# STM32C593xx register map
File version: 1.0
Registers are 32-bit, read-write, reset 0x0 unless marked. A register's access mark holds for its fields unless they carry their own. Offsets are from the block's base; [hi:lo] are bit positions; {n}, {i} and the like mark numbered series; 'fields as' and 'values as' point back to an identical list.

## ETH1 — Ethernet Peripheral
Base 0x40028000
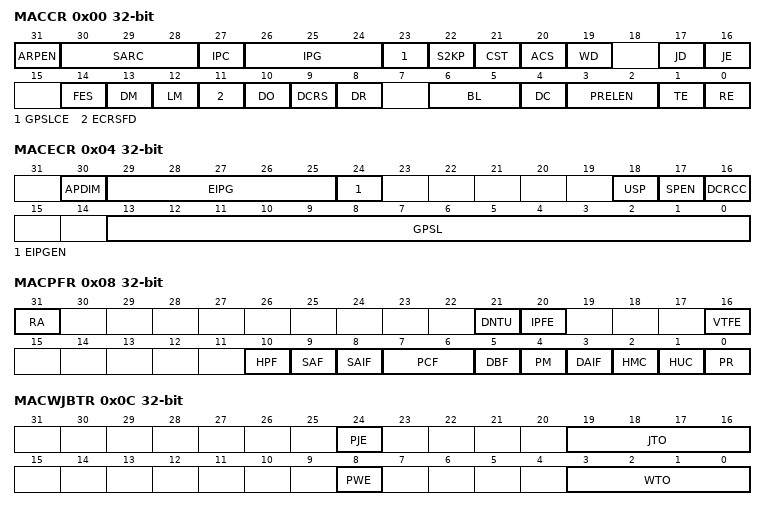
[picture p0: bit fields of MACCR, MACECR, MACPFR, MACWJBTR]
0x00 MACCR — Operating mode configuration register
  [31] ARPEN — ARP Offload Enable
  [30:28] SARC
  [27] IPC — Checksum Offload
  [26:24] IPG — Inter-Packet Gap
  [23] GPSLCE
  [22] S2KP
  [21] CST
  [20] ACS
  [19] WD — Watchdog Disable
  [17] JD — Jabber Disable
  [16] JE — Jumbo Packet Enable
  [14] FES — MAC Speed
  [13] DM — Duplex Mode
  [12] LM — Loopback Mode
  [11] ECRSFD
  [10] DO — Disable Receive Own
  [9] DCRS
  [8] DR — Disable Retry
  [6:5] BL — Back-Off Limit
  [4] DC — Deferral Check
  [3:2] PRELEN
  [1] TE — Transmitter Enable
  [0] RE — Receiver Enable
0x04 MACECR — Extended operating mode configuration register
  [30] APDIM
  [29:25] EIPG — Extended Inter-Packet Gap
  [24] EIPGEN
  [18] USP
  [17] SPEN
  [16] DCRCC
  [13:0] GPSL — Giant Packet Size Limit
0x08 MACPFR — Packet filtering control register
  [31] RA — Receive All
  [21] DNTU
  [20] IPFE
  [16] VTFE — VLAN Tag Filter Enable
  [10] HPF — Hash or Perfect Filter
  [9] SAF — Source Address Filter Enable
  [8] SAIF — SA Inverse Filtering
  [7:6] PCF — Pass Control Packets
  [5] DBF — Disable Broadcast Packets
  [4] PM — Pass All Multicast
  [3] DAIF — DA Inverse Filtering
  [2] HMC — Hash Multicast
  [1] HUC — Hash Unicast
  [0] PR — Promiscuous Mode
0x0C MACWJBTR — Watchdog and jabber timeout register
  [24] PJE — Programmable Jabber Enable
  [19:16] JTO — Jabber Timeout
  [8] PWE — Programmable Watchdog Enable
  [3:0] WTO — Watchdog Timeout
0x10 MACHT0R — Hash Table 0 register
  [31:0] HT31T0 — MAC Hash Table First 32 Bits
0x14 MACHT1R — Hash Table 1 register
  [31:0] HT63T32 — MAC Hash Table Second 32 Bits
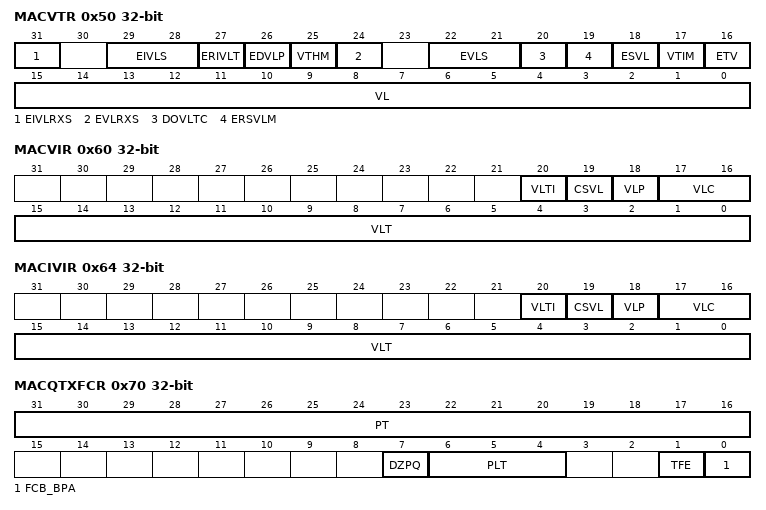
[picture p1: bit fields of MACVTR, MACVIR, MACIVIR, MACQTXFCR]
0x50 MACVTR — VLAN tag register
  [31] EIVLRXS
  [29:28] EIVLS
  [27] ERIVLT — Enable Inner VLAN Tag
  [26] EDVLP — Enable Double VLAN Processing
  [25] VTHM
  [24] EVLRXS — Enable VLAN Tag in Rx status
  [22:21] EVLS
  [20] DOVLTC — Disable VLAN Type Check
  [19] ERSVLM — Enable Receive S-VLAN Match
  [18] ESVL — Enable S-VLAN
  [17] VTIM — VLAN Tag Inverse Match Enable
  [16] ETV
  [15:0] VL
0x58 MACVHTR — VLAN Hash table register
  [15:0] VLHT — VLAN Hash Table
0x60 MACVIR — VLAN inclusion register
  [20] VLTI — VLAN Tag Input
  [19] CSVL — C-VLAN or S-VLAN
  [18] VLP — VLAN Priority Control
  [17:16] VLC
  [15:0] VLT — VLAN Tag for Transmit Packets
0x64 MACIVIR — Inner VLAN inclusion register
  fields as MACVIR
0x70 MACQTXFCR — Tx Queue flow control register
  [31:16] PT — Pause Time
  [7] DZPQ — Disable Zero-Quanta Pause
  [6:4] PLT — Pause Low Threshold
  [1] TFE — Transmit Flow Control Enable
  [0] FCB_BPA
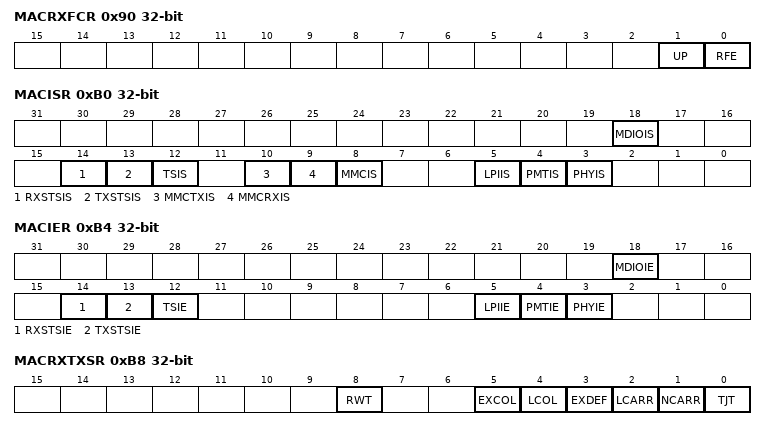
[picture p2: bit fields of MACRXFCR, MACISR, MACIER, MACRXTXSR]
0x90 MACRXFCR — Rx flow control register
  [1] UP — Unicast Pause Packet Detect
  [0] RFE — Receive Flow Control Enable
0xB0 MACISR — Interrupt status register
  [18] MDIOIS — MDIO Interrupt Status
  [14] RXSTSIS — Receive Status Interrupt
  [13] TXSTSIS — Transmit Status Interrupt
  [12] TSIS — Timestamp Interrupt Status
  [10] MMCTXIS — MMC Transmit Interrupt Status
  [9] MMCRXIS — MMC Receive Interrupt Status
  [8] MMCIS — MMC Interrupt Status
  [5] LPIIS — LPI Interrupt Status
  [4] PMTIS — PMT Interrupt Status
  [3] PHYIS — PHY Interrupt
0xB4 MACIER — Interrupt enable register
  [18] MDIOIE — MDIO Interrupt Enable
  [14] RXSTSIE
  [13] TXSTSIE
  [12] TSIE — Timestamp Interrupt Enable
  [5] LPIIE — LPI Interrupt Enable
  [4] PMTIE — PMT Interrupt Enable
  [3] PHYIE — PHY Interrupt Enable
0xB8 MACRXTXSR — Rx Tx status register
  [8] RWT — Receive Watchdog Timeout
  [5] EXCOL — Excessive Collisions
  [4] LCOL — Late Collision
  [3] EXDEF — Excessive Deferral
  [2] LCARR — Loss of Carrier
  [1] NCARR — No Carrier
  [0] TJT — Transmit Jabber Timeout
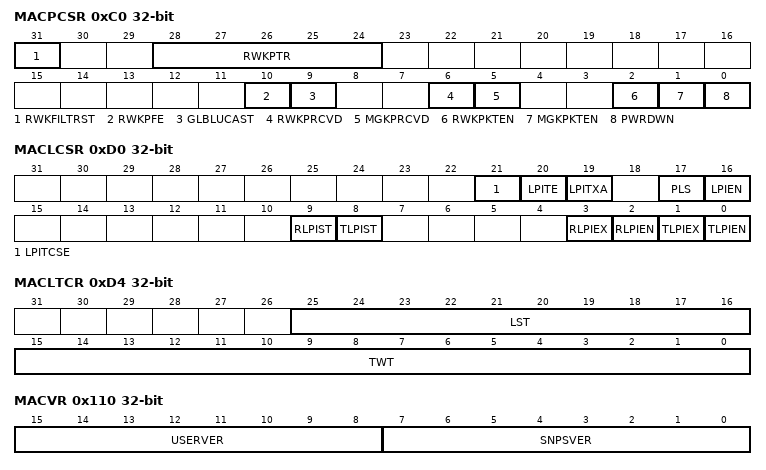
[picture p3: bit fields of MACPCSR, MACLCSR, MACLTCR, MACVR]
0xC0 MACPCSR — PMT control status register
  [31] RWKFILTRST
  [28:24] RWKPTR — Remote wake-up FIFO Pointer
  [10] RWKPFE
  [9] GLBLUCAST — Global Unicast
  [6] RWKPRCVD
  [5] MGKPRCVD — Magic Packet Received
  [2] RWKPKTEN — Remote wake-up Packet Enable
  [1] MGKPKTEN — Magic Packet Enable
  [0] PWRDWN — Power Down
0xC4 MACRWKPFR — Remote wake-up packet filter register
  [31:0] MACRWKPFR — Remote wake-up packet filter
0xD0 MACLCSR — LPI control and status register
  [21] LPITCSE — LPI Tx Clock Stop Enable
  [20] LPITE — LPI Timer Enable
  [19] LPITXA — LPI Tx Automate
  [17] PLS — PHY Link Status
  [16] LPIEN — LPI Enable
  [9] RLPIST — Receive LPI State
  [8] TLPIST — Transmit LPI State
  [3] RLPIEX — Receive LPI Exit
  [2] RLPIEN — Receive LPI Entry
  [1] TLPIEX — Transmit LPI Exit
  [0] TLPIEN — Transmit LPI Entry
0xD4 MACLTCR — LPI timers control register
  [25:16] LST — LPI LS Timer
  [15:0] TWT — LPI TW Timer
0xD8 MACLETR — LPI entry timer register
  [19:0] LPIET — LPI Entry Timer
0xDC MAC1USTCR — One-microsecond-tick counter register
  [11:0] TIC_1US_CNTR — 1 micro s tick Counter
0x110 MACVR ro — Version register
  [15:8] USERVER — ST-defined version
  [7:0] SNPSVER — IP version
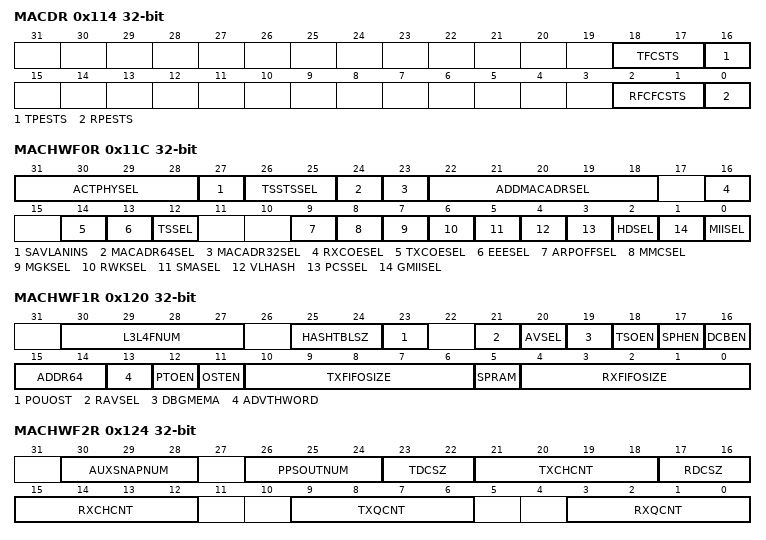
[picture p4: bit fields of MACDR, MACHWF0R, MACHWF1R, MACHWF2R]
0x114 MACDR ro — Debug register
  [18:17] TFCSTS, [16] TPESTS, [2:1] RFCFCSTS, [0] RPESTS
0x11C MACHWF0R ro — HW feature 0 register
  [31:28] ACTPHYSEL — Active PHY selected
  [27] SAVLANINS
  [26:25] TSSTSSEL — Timestamp System Time Source
  [24] MACADR64SEL — MAC Addresses 64-127 Selected
  [23] MACADR32SEL — MAC Addresses 32-63 Selected
  [22:18] ADDMACADRSEL — MAC Addresses 1-31 Selected
  [16] RXCOESEL
  [14] TXCOESEL
  [13] EEESEL
  [12] TSSEL
  [9] ARPOFFSEL — ARP Offload Enabled
  [8] MMCSEL — RMON Module Enable
  [7] MGKSEL — PMT Magic Packet Enable
  [6] RWKSEL
  [5] SMASEL — SMA (MDIO) Interface
  [4] VLHASH — VLAN Hash Filter Selected
  [3] PCSSEL
  [2] HDSEL — Half-duplex Support
  [1] GMIISEL — 1000 Mbps Support
  [0] MIISEL — 10 or 100 Mbps Support
0x120 MACHWF1R ro — HW feature 1 register
  [30:27] L3L4FNUM
  [25:24] HASHTBLSZ — Hash Table Size
  [23] POUOST
  [21] RAVSEL
  [20] AVSEL — AV Feature Enable
  [19] DBGMEMA — DMA Debug Registers Enable
  [18] TSOEN
  [17] SPHEN — Split Header Feature Enable
  [16] DCBEN — DCB Feature Enable
  [15:14] ADDR64 — Address width
  [13] ADVTHWORD
  [12] PTOEN — PTP Offload Enable
  [11] OSTEN — One-Step Timestamping Enable
  [10:6] TXFIFOSIZE — MTL Transmit FIFO Size
  [5] SPRAM — Single Port RAM Enable
  [4:0] RXFIFOSIZE — MTL Receive FIFO Size
0x124 MACHWF2R ro — HW feature 2 register
  [30:28] AUXSNAPNUM
  [26:24] PPSOUTNUM — Number of PPS Outputs
  [23:22] TDCSZ
  [21:18] TXCHCNT
  [17:16] RDCSZ
  [15:12] RXCHCNT
  [9:6] TXQCNT — Number of MTL Transmit Queues
  [3:0] RXQCNT — Number of MTL Receive Queues
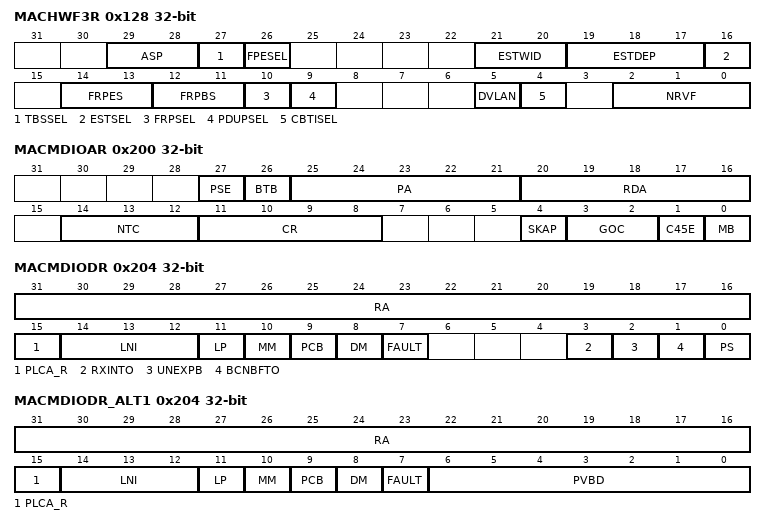
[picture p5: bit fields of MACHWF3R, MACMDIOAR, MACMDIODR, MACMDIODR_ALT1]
0x128 MACHWF3R ro — HW feature 3 register
  [29:28] ASP — Automotive Safety Package
  [27] TBSSEL — Time-based scheduling Enable
  [26] FPESEL — Frame Preemption Enable
  [21:20] ESTWID
  [19:17] ESTDEP
  [16] ESTSEL
  [14:13] FRPES
  [12:11] FRPBS
  [10] FRPSEL
  [9] PDUPSEL
  [5] DVLAN — Double VLAN processing enable
  [4] CBTISEL
  [2:0] NRVF
0x200 MACMDIOAR — MDIO address register
  [27] PSE — Preamble Suppression Enable
  [26] BTB — Back to Back transactions
  [25:21] PA — Physical Layer Address
  [20:16] RDA — Register/Device Address
  [14:12] NTC — Number of Training Clocks
  [11:8] CR — CSR Clock Range
  [4] SKAP — Skip Address Packet
  [3:2] GOC — MII Operation Command
  [1] C45E — Clause 45 PHY Enable
  [0] MB — MII Busy
0x204 MACMDIODR — MDIO data register
  [31:16] RA — Register Address
  [15] PLCA_R — PLCA software reset
  [14:12] LNI — Local_nodeID
  [11] LP — Low power
  [10] MM — Multidrop mode
  [9] PCB — PCS collision bit
  [8] DM — Duplex mode
  [7] FAULT
  [3] RXINTO
  [2] UNEXPB — Unexpected BEACON
  [1] BCNBFTO
  [0] PS — PLCA status
0x204 MACMDIODR_ALT1 (alternate view of MACMDIODR) — MDIO data register
  [31:16] RA — Register Address
  [15] PLCA_R — PLCA software reset
  [14:12] LNI — Local_nodeID
  [11] LP — Low power
  [10] MM — Multidrop mode
  [9] PCB — PCS collision bit
  [8] DM — Duplex mode
  [7] FAULT
  [6:0] PVBD — PLCA Variable Buffer Depth
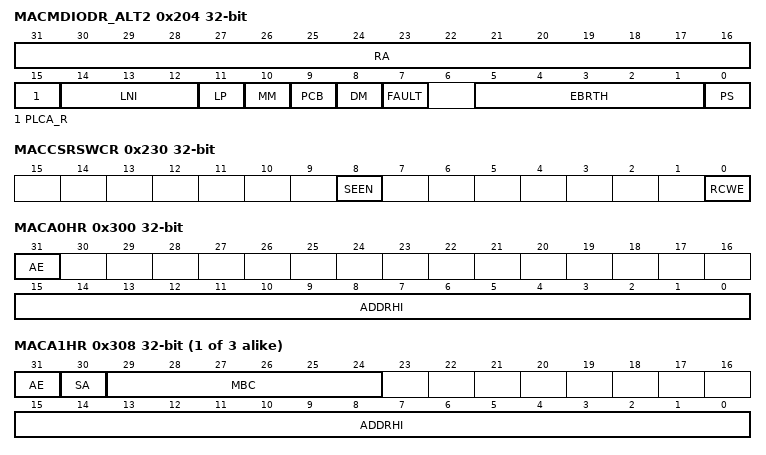
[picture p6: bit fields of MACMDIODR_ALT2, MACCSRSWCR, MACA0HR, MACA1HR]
0x204 MACMDIODR_ALT2 (alternate view of MACMDIODR) — MDIO data register
  [31:16] RA — Register Address
  [15] PLCA_R — PLCA software reset
  [14:12] LNI — Local_nodeID
  [11] LP — Low power
  [10] MM — Multidrop mode
  [9] PCB — PCS collision bit
  [8] DM — Duplex mode
  [7] FAULT
  [5:1] EBRTH
  [0] PS — PLCA status
0x210 MACARPAR — ARP address register
  [31:0] ARPPA — ARP Protocol Address
0x230 MACCSRSWCR — CSR software control register
  [8] SEEN — Slave Error Response Enable
  [0] RCWE
0x240 MACPRSTIMR — MAC presentation time register
  [31:0] MPTN
0x244 MACPRSTIMUR — MAC presentation time update register
  [31:0] MPTU
0x300 MACA0HR — MAC Address 0 high register
  [31] AE — Address Enable
  [15:0] ADDRHI — MAC Address0[47:32]
{0x304+8i} MACA{i}LR (i=0..3) — MAC Address {i} low register
  [31:0] ADDRLO — MAC Address x [31:0]
{0x300+8i} MACA{i}HR (i=1..3) — MAC Address {i} high register
  [31] AE — Address Enable
  [30] SA — Source Address
  [29:24] MBC — Mask Byte Control
  [15:0] ADDRHI — MAC Address1 [47:32]
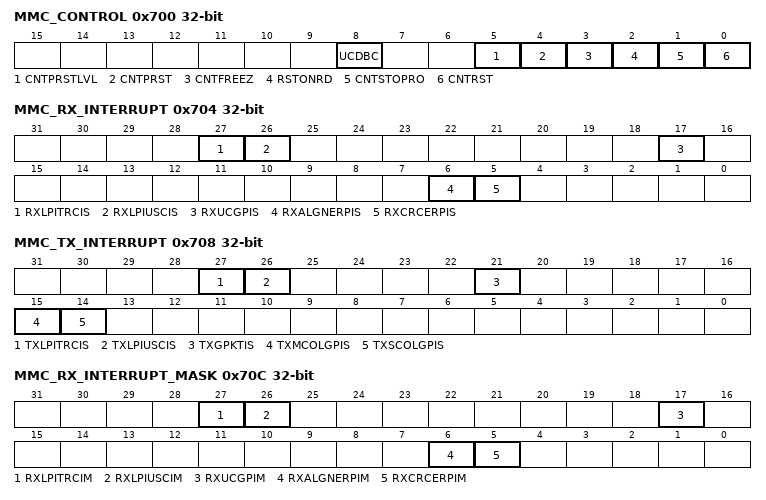
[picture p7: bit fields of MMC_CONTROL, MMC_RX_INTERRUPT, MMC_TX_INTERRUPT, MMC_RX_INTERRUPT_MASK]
0x700 MMC_CONTROL
  [8] UCDBC
  [5] CNTPRSTLVL — Full-Half Preset
  [4] CNTPRST — Counters Preset
  [3] CNTFREEZ — MMC Counter Freeze
  [2] RSTONRD — Reset on Read
  [1] CNTSTOPRO — Counter Stop Rollover
  [0] CNTRST — Counters Reset
0x704 MMC_RX_INTERRUPT
  [27] RXLPITRCIS — MMC Receive LPI transition counter interrupt status
  [26] RXLPIUSCIS — MMC Receive LPI microsecond counter interrupt status
  [17] RXUCGPIS — MMC Receive Unicast Good Packet Counter Interrupt Status
  [6] RXALGNERPIS — MMC Receive Alignment Error Packet Counter Interrupt Status
  [5] RXCRCERPIS — MMC Receive CRC Error Packet Counter Interrupt Status
0x708 MMC_TX_INTERRUPT
  [27] TXLPITRCIS — MMC Transmit LPI transition counter interrupt status
  [26] TXLPIUSCIS — MMC Transmit LPI microsecond counter interrupt status
  [21] TXGPKTIS — MMC Transmit Good Packet Counter Interrupt Status
  [15] TXMCOLGPIS — MMC Transmit Multiple Collision Good Packet Counter Interrupt Status
  [14] TXSCOLGPIS — MMC Transmit Single Collision Good Packet Counter Interrupt Status
0x70C MMC_RX_INTERRUPT_MASK
  [27] RXLPITRCIM — MMC Receive LPI transition counter interrupt Mask
  [26] RXLPIUSCIM — MMC Receive LPI microsecond counter interrupt Mask
  [17] RXUCGPIM — MMC Receive Unicast Good Packet Counter Interrupt Mask
  [6] RXALGNERPIM — MMC Receive Alignment Error Packet Counter Interrupt Mask
  [5] RXCRCERPIM — MMC Receive CRC Error Packet Counter Interrupt Mask
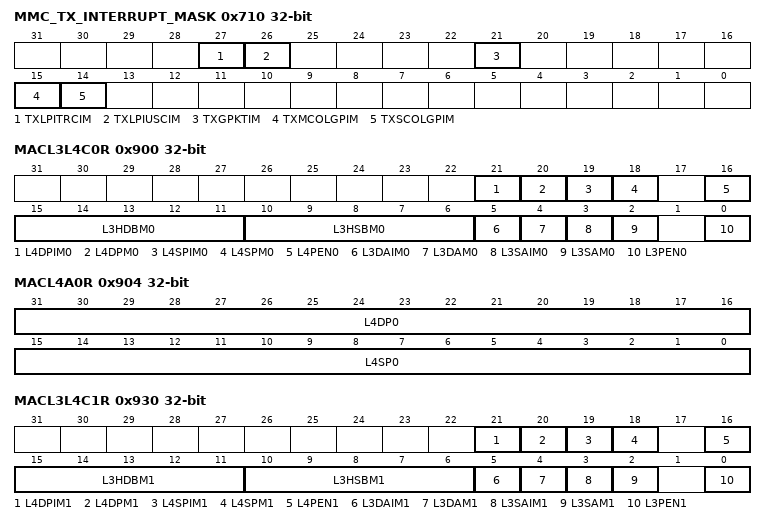
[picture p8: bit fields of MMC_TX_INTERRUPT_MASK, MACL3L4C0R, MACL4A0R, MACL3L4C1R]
0x710 MMC_TX_INTERRUPT_MASK
  [27] TXLPITRCIM — MMC Transmit LPI transition counter interrupt Mask
  [26] TXLPIUSCIM — MMC Transmit LPI microsecond counter interrupt Mask
  [21] TXGPKTIM — MMC Transmit Good Packet Counter Interrupt Mask
  [15] TXMCOLGPIM — MMC Transmit Multiple Collision Good Packet Counter Interrupt Mask
  [14] TXSCOLGPIM — MMC Transmit Single Collision Good Packet Counter Interrupt Mask
0x74C TX_SINGLE_COLLISION_GOOD_PACKETS ro
  [31:0] TXSNGLCOLG — Tx Single Collision Good Packets
0x750 TX_MULTIPLE_COLLISION_GOOD_PACKETS ro
  [31:0] TXMULTCOLG — Tx Multiple Collision Good Packets
0x768 TX_PACKET_COUNT_GOOD ro
  [31:0] TXPKTG — Tx Packet Count Good
0x794 RX_CRC_ERROR_PACKETS ro
  [31:0] RXCRCERR — Rx CRC Error Packets
0x798 RX_ALIGNMENT_ERROR_PACKETS ro
  [31:0] RXALGNERR — Rx Alignment Error Packets
0x7C4 RX_UNICAST_PACKETS_GOOD ro
  [31:0] RXUCASTG — Rx Unicast Packets Good
0x7EC TX_LPI_USEC_CNTR ro — Tx LPI microsecond timer register
  [31:0] TXLPIUSC — Tx LPI Microseconds Counter
0x7F0 TX_LPI_TRAN_CNTR ro — Tx LPI transition counter register
  [31:0] TXLPITRC — Tx LPI Transition counter
0x7F4 RX_LPI_USEC_CNTR ro — Rx LPI microsecond counter register
  [31:0] RXLPIUSC — Rx LPI Microseconds Counter
0x7F8 RX_LPI_TRAN_CNTR ro — Rx LPI transition counter register
  [31:0] RXLPITRC — Rx LPI Transition counter
0x900 MACL3L4C0R — L3 and L4 control 0 register
  [21] L4DPIM0
  [20] L4DPM0
  [19] L4SPIM0
  [18] L4SPM0
  [16] L4PEN0 — Layer 4 Protocol Enable
  [15:11] L3HDBM0
  [10:6] L3HSBM0
  [5] L3DAIM0
  [4] L3DAM0 — Layer 3 IP DA Match Enable
  [3] L3SAIM0
  [2] L3SAM0 — Layer 3 IP SA Match Enable
  [0] L3PEN0 — Layer 3 Protocol Enable
0x904 MACL4A0R — Layer4 Address filter 0 register
  [31:16] L4DP0, [15:0] L4SP0
0x910 MACL3A00R — Layer3 Address 0 filter 0 register
  [31:0] L3A00 — Layer 3 Address 0 Field
0x914 MACL3A10R — Layer3 Address 1 filter 0 register
  [31:0] L3A10 — Layer 3 Address 1 Field
0x918 MACL3A20R — Layer3 Address 2 filter 0 register
  [31:0] L3A20 — Layer 3 Address 2 Field
0x91C MACL3A30R — Layer3 Address 3 filter 0 register
  [31:0] L3A30 — Layer 3 Address 3 Field
0x930 MACL3L4C1R — L3 and L4 control 1 register
  [21] L4DPIM1
  [20] L4DPM1
  [19] L4SPIM1
  [18] L4SPM1
  [16] L4PEN1 — Layer 4 Protocol Enable
  [15:11] L3HDBM1
  [10:6] L3HSBM1
  [5] L3DAIM1
  [4] L3DAM1 — Layer 3 IP DA Match Enable
  [3] L3SAIM1
  [2] L3SAM1 — Layer 3 IP SA Match Enable
  [0] L3PEN1 — Layer 3 Protocol Enable
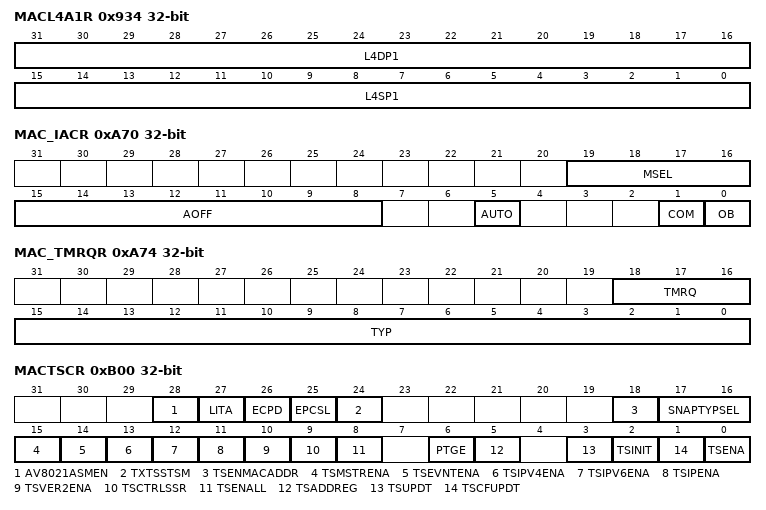
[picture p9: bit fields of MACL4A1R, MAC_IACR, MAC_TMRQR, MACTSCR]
0x934 MACL4A1R — Layer 4 address filter 1 register
  [31:16] L4DP1, [15:0] L4SP1
0x940 MACL3A01R — Layer3 address 0 filter 1 Register
  [31:0] L3A01 — Layer 3 Address 0 Field
0x944 MACL3A11R — Layer3 address 1 filter 1 register
  [31:0] L3A11 — Layer 3 Address 1 Field
0x948 MACL3A21R — Layer3 address 2 filter 1 Register
  [31:0] L3A21 — Layer 3 Address 2 Field
0x94C MACL3A31R — Layer3 address 3 filter 1 register
  [31:0] L3A31 — Layer 3 Address 3 Field
0xA70 MAC_IACR — MAC Indirect Access Control register
  [19:16] MSEL — Mode Select
  [15:8] AOFF — Address Offset
  [5] AUTO — Auto-increment
  [1] COM — Command type
  [0] OB — Operation Busy
0xA74 MAC_TMRQR — MAC type-based Rx Queue mapping register
  [18:16] TMRQ — Type Match Rx Queue Number
  [15:0] TYP — Type field Value
0xB00 MACTSCR — Timestamp control Register
  [28] AV8021ASMEN — AV 802.1AS Mode Enable
  [27] LITA
  [26] ECPD
  [25] EPCSL — Enable PCS latencies
  [24] TXTSSTSM
  [18] TSENMACADDR
  [17:16] SNAPTYPSEL
  [15] TSMSTRENA
  [14] TSEVNTENA
  [13] TSIPV4ENA
  [12] TSIPV6ENA
  [11] TSIPENA
  [10] TSVER2ENA
  [9] TSCTRLSSR
  [8] TSENALL
  [6] PTGE
  [5] TSADDREG — Update Addend Register
  [3] TSUPDT — Update Timestamp
  [2] TSINIT — Initialize Timestamp
  [1] TSCFUPDT
  [0] TSENA — Enable Timestamp
0xB04 MACSSIR — Subsecond increment register
  [23:16] SSINC — Subsecond Increment Value
0xB08 MACSTSR ro — System time seconds register
  [31:0] TSS — Timestamp Second
0xB0C MACSTNR ro — System time nanoseconds register
  [30:0] TSSS — Timestamp subseconds
0xB10 MACSTSUR — System time seconds update register
  [31:0] TSS — Timestamp Seconds
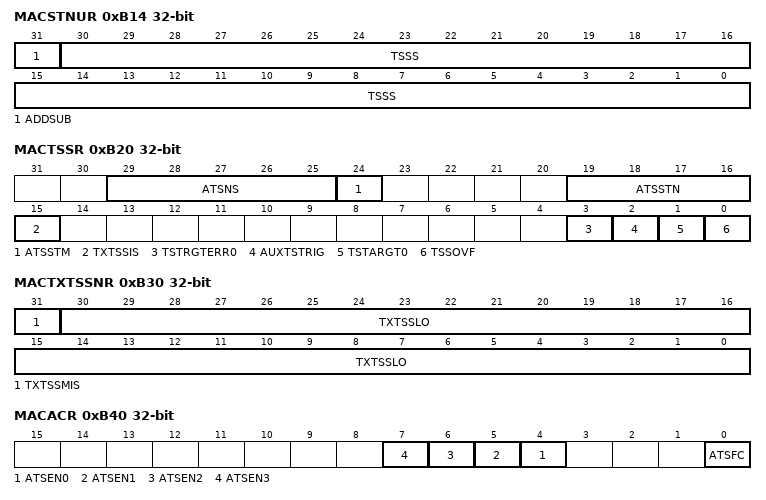
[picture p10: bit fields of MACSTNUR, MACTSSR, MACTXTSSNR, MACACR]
0xB14 MACSTNUR — System time nanoseconds update register
  [31] ADDSUB — Add or Subtract Time
  [30:0] TSSS — Timestamp subseconds
0xB18 MACTSAR — Timestamp addend register
  [31:0] TSAR — Timestamp Addend Register
0xB20 MACTSSR — Timestamp status register
  [29:25] ATSNS
  [24] ATSSTM
  [19:16] ATSSTN
  [15] TXTSSIS
  [3] TSTRGTERR0 — Timestamp Target Time Error
  [2] AUXTSTRIG
  [1] TSTARGT0 — Timestamp Target Time Reached
  [0] TSSOVF — Timestamp Seconds Overflow
0xB24 MACRXDTI — Rx domain time increment register
  [31:16] RXNS
0xB28 MACTXDTI — Tx domain time increment register
  [31:16] TXNS
0xB30 MACTXTSSNR — Tx timestamp status nanoseconds register
  [31] TXTSSMIS
  [30:0] TXTSSLO — Transmit Timestamp Status Low
0xB34 MACTXTSSSR ro — Tx timestamp status seconds register
  [31:0] TXTSSHI
0xB40 MACACR — Auxiliary control register
  [n+4] ATSEN{n} (n=0..3) — Auxiliary Snapshot {n} Enable
  [0] ATSFC — Auxiliary Snapshot FIFO Clear
0xB48 MACATSNR ro — Auxiliary timestamp nanoseconds register
  [30:0] AUXTSLO — Auxiliary Timestamp
0xB4C MACATSSR ro — Auxiliary timestamp seconds register
  [31:0] AUXTSHI — Auxiliary Timestamp
0xB50 MACTSIACR — Timestamp ingress asymmetric correction register
  [31:0] OSTIAC
0xB54 MACTSEACR — Timestamp egress asymmetric correction register
  [31:0] OSTEAC
0xB58 MACTSICNR — Timestamp Ingress correction nanosecond register
  [31:0] TSIC — Timestamp Ingress Correction
0xB5C MACTSECNR — Timestamp egress correction nanosecond register
  [31:0] TSEC — Timestamp Egress Correction
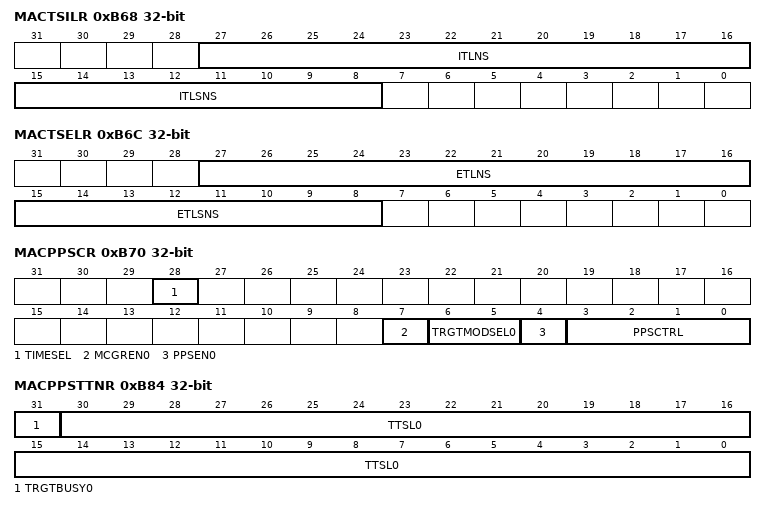
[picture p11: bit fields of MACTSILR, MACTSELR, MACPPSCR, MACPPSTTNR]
0xB68 MACTSILR ro — Timestamp Ingress Latency register
  [27:16] ITLNS, [15:8] ITLSNS
0xB6C MACTSELR ro — Timestamp Egress Latency register
  [27:16] ETLNS, [15:8] ETLSNS
0xB70 MACPPSCR — PPS control register
  [28] TIMESEL — Time Select
  [7] MCGREN0
  [6:5] TRGTMODSEL0
  [4] PPSEN0
  [3:0] PPSCTRL — PPS Output Frequency Control
0xB80 MACPPSTTSR — PPS target time seconds register
  [31:0] TSTRH0
0xB84 MACPPSTTNR — PPS target time nanoseconds register
  [31] TRGTBUSY0 — PPS Target Time Register Busy
  [30:0] TTSL0
0xB88 MACPPSIR — PPS interval register
  [31:0] PPSINT0 — PPS Output Signal Interval
0xB8C MACPPSWR — PPS width register
  [31:0] PPSWIDTH0 — PPS Output Signal Width
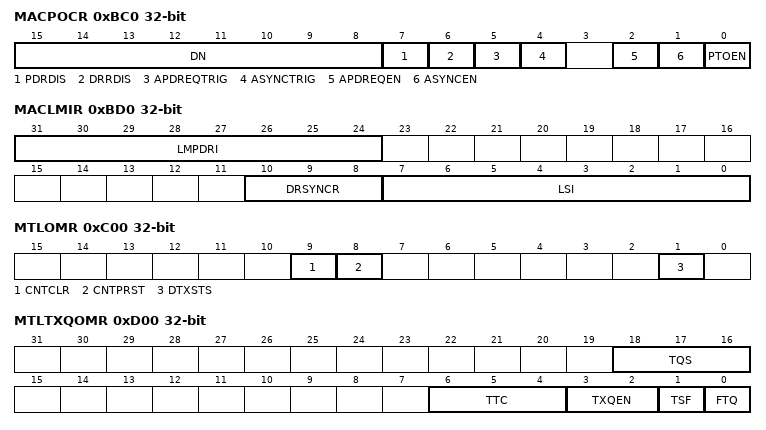
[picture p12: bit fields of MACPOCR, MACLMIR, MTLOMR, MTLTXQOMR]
0xBC0 MACPOCR — PTP Offload control register
  [15:8] DN — Domain Number
  [7] PDRDIS
  [6] DRRDIS
  [5] APDREQTRIG
  [4] ASYNCTRIG
  [2] APDREQEN
  [1] ASYNCEN
  [0] PTOEN — PTP Offload Enable
0xBC4 MACSPI0R — PTP Source Port Identity 0 Register
  [31:0] SPI0 — Source Port Identity 0
0xBC8 MACSPI1R — PTP Source port identity 1 register
  [31:0] SPI1 — Source Port Identity 1
0xBCC MACSPI2R — PTP Source port identity 2 register
  [15:0] SPI2 — Source Port Identity 2
0xBD0 MACLMIR — Log message interval register
  [31:24] LMPDRI — Log Min Pdelay_Req Interval
  [10:8] DRSYNCR — Delay_Req to SYNC Ratio
  [7:0] LSI — Log Sync Interval
0xC00 MTLOMR — Operating mode register
  [9] CNTCLR — Counters Reset
  [8] CNTPRST — Counters Preset
  [1] DTXSTS — Drop Transmit Status
0xC20 MTLISR ro — Interrupt status register
  [0] Q0IS — Queue interrupt status
0xD00 MTLTXQOMR — Tx queue operating mode register
  [18:16] TQS — Transmit queue size
  [6:4] TTC — Transmit Threshold Control
  [3:2] TXQEN — Transmit Queue Enable
  [1] TSF — Transmit Store and Forward
  [0] FTQ — Flush Transmit Queue
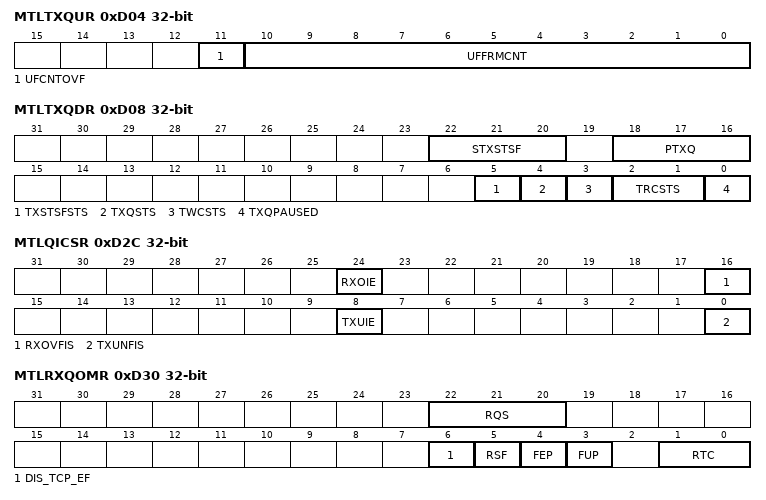
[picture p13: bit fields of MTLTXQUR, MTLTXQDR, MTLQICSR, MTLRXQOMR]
0xD04 MTLTXQUR — Tx queue underflow register
  [11] UFCNTOVF
  [10:0] UFFRMCNT — Underflow Packet Counter
0xD08 MTLTXQDR ro — Tx queue debug register
  [22:20] STXSTSF
  [18:16] PTXQ
  [5] TXSTSFSTS
  [4] TXQSTS — MTL Tx Queue Not Empty Status
  [3] TWCSTS
  [2:1] TRCSTS
  [0] TXQPAUSED — Transmit Queue in Pause
0xD2C MTLQICSR — Queue interrupt control status register
  [24] RXOIE, [16] RXOVFIS, [8] TXUIE, [0] TXUNFIS
0xD30 MTLRXQOMR — Rx queue operating mode register
  [22:20] RQS — Receive Queue Size
  [6] DIS_TCP_EF
  [5] RSF
  [4] FEP — Forward Error Packets
  [3] FUP
  [1:0] RTC
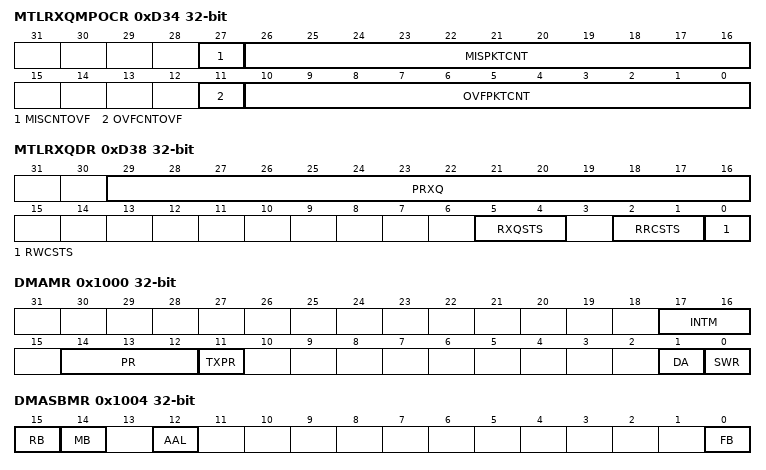
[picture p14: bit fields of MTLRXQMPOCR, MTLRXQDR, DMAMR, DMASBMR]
0xD34 MTLRXQMPOCR — Rx queue missed packet and overflow counter register
  [27] MISCNTOVF
  [26:16] MISPKTCNT — Missed Packet Counter
  [11] OVFCNTOVF — Overflow Counter Overflow Bit
  [10:0] OVFPKTCNT — Overflow Packet Counter
0xD38 MTLRXQDR ro — Rx queue debug register
  [29:16] PRXQ, [5:4] RXQSTS, [2:1] RRCSTS, [0] RWCSTS
0x1000 DMAMR — DMA mode register
  [17:16] INTM — Interrupt Mode
  [14:12] PR — Priority ratio
  [11] TXPR — Transmit priority
  [1] DA
  [0] SWR — Software Reset
0x1004 DMASBMR — System bus mode register
  [15] RB — Rebuild INCRx Burst
  [14] MB — Mixed Burst
  [12] AAL — Address-Aligned Beats
  [0] FB — Fixed Burst Length
0x1008 DMAISR ro — Interrupt status register
  [17] MACIS — MAC Interrupt Status
  [16] MTLIS — MTL Interrupt Status
  [0] DC0IS — DMA Channel Interrupt Status
0x100C DMADSR ro — Debug status register
  [15:12] TPS0
  [11:8] RPS0
  [0] AXWHSTS — AHB Master Write Channel
0x1100 DMACCR — Channel control register
  [26] DRO
  [20:18] DSL — Descriptor Skip Length
  [16] PBLX8 — 8xPBL mode
  [13:0] MSS — Maximum Segment Size
0x1104 DMACTXCR — Channel transmit control register
  [21:16] TXPBL
  [12] TSE — TCP Segmentation Enabled
  [4] OSF — Operate on Second Packet
  [0] ST
0x1108 DMACRXCR — Channel receive control register
  [31] RPF — DMA Rx Channel Packet Flush
  [21:16] RXPBL
  [14:1] RBSZ — Receive Buffer size
  [0] SR — Start or Stop Receive
0x1114 DMACTXDLAR — Channel Tx descriptor list address register
  [31:0] TDESLA — Start of Transmit List
0x111C DMACRXDLAR — Channel Rx descriptor list address register
  [31:0] RDESLA — Start of Receive List
0x1120 DMACTXDTPR — Channel Tx descriptor tail pointer register
  [31:0] TDT
0x1128 DMACRXDTPR — Channel Rx descriptor tail pointer register
  [31:0] RDT
0x112C DMACTXRLR — Channel Tx descriptor ring length register
  [9:0] TDRL
0x1130 DMACRXRLR — Channel Rx descriptor ring length register
  [23:16] ARBS — Alternate Receive Buffer Size
  [9:0] RDRL
0x1134 DMACIER — Channel interrupt enable register
  [15] NIE
  [14] AIE
  [13] CDEE
  [12] FBEE — Fatal Bus Error Enable
  [11] ERIE
  [10] ETIE
  [9] RWTE
  [8] RSE — Receive Stopped Enable
  [7] RBUE
  [6] RIE — Receive Interrupt Enable
  [2] TBUE
  [1] TXSE — Transmit Stopped Enable
  [0] TIE — Transmit Interrupt Enable
0x1138 DMACRXIWTR — Channel Rx interrupt watchdog timer register
  [31] PSEL — Packet Count Interrupt Select
  [29:20] RBCT — Receive Byte Count Threshold
  [19:18] ITCU — Rx Idle Timer Count Units
  [17:16] RWTU
  [12:8] ITW — Rx Idle Timer Window
  [7:0] RWT
0x1144 DMACCATXDR ro — Channel current application transmit descriptor register
  [31:0] CURTDESAPTR
0x114C DMACCARXDR ro — Channel current application receive descriptor register
  [31:0] CURRDESAPTR
0x1154 DMACCATXBR ro — Channel current application transmit buffer register
  [31:0] CURTBUFAPTR
0x115C DMACCARXBR ro — Channel current application receive buffer register
  [31:0] CURRBUFAPTR
0x1160 DMACSR — Channel status register
  [21:19] REB — Rx DMA Error Bits
  [18:16] TEB — Tx DMA Error Bits
  [15] NIS — Normal Interrupt Summary
  [14] AIS — Abnormal Interrupt Summary
  [13] CDE — Context Descriptor Error
  [12] FBE — Fatal Bus Error
  [11] ERI — Early Receive Interrupt
  [10] ETI — Early Transmit Interrupt
  [9] RWT — Receive Watchdog Timeout
  [8] RPS — Receive Process Stopped
  [7] RBU — Receive Buffer Unavailable
  [6] RI — Receive Interrupt
  [2] TBU — Transmit Buffer Unavailable
  [1] TPS — Transmit Process Stopped
  [0] TI — Transmit Interrupt
0x1164 DMACMFCR — Channel missed frame count register
  [15] MFCO
  [10:0] MFC — Dropped Packet Counters
